VERSION ""

NS_ :

BS_:

BU_: VCU INVOBC
VAL_TABLE_ Vt_INVCH_SignalDSP_state 43 "CTRL_STATE_EXPORT_SHUTDOWN_4" 42 "CTRL_STATE_EXPORT_SHUTDOWN_3" 41 "CTRL_STATE_EXPORT_SHUTDOWN_2" 40 "CTRL_STATE_EXPORT_SHUTDOWN_1" 39 "CTRL_STATE_NA" 38 "CTRL_STATE_NA" 37 "CTRL_STATE_NA" 36 "CTRL_STATE_NA" 35 "CTRL_STATE_NA" 34 "CTRL_STATE_EXPORT_ALCI" 33 "CTRL_STATE_EXPORT_SHUTDOWN" 32 "CTRL_STATE_EXPORT_ENERGY" 31 "CTRL_STATE_EXPORT_DISABLED" 30 "CTRL_STATE_EXPORT_INIT" 29 "CTRL_STATE_NA" 28 "CTRL_STATE_NA" 27 "CTRL_STATE_NA" 26 "CTRL_STATE_NA" 25 "CTRL_STATE_NA" 24 "CTRL_STATE_NA" 23 "CTRL_STATE_CHARGER_SHUTDOWN_4" 22 "CTRL_STATE_CHARGER_SHUTDOWN_3" 21 "CTRL_STATE_CHARGER_SHUTDOWN_2" 20 "CTRL_STATE_CHARGER_SHUTDOWN_1" 19 "CTRL_STATE_NA" 18 "CTRL_STATE_NA" 17 "CTRL_STATE_NA" 16 "CTRL_STATE_NA" 15 "CTRL_STATE_VEHICLE_DOWN_CHARGER" 14 "CTRL_STATE_VEHICLE_ERROR" 13 "CTRL_STATE_VEHICLE_ENERGY_DISC_E" 12 "CTRL_STATE_VEHICLE_ACCEPT_CD" 11 "CTRL_STATE_VEHICLE_CONNECTED_B" 10 "CTRL_STATE_VEHICLE_NOT_CON_A" 9 "CTRL_STATE_MODULE_DEBUG" 8 "CTRL_STATE_MODULE_STAND_BY" 7 "CTRL_STATE_MODULE_EXPORT" 6 "CTRL_STATE_MODULE_TEST" 5 "CTRL_STATE_MODULE_DELAYED_SLEEP" 4 "CTRL_STATE_MODULE_SLEEP" 3 "CTRL_STATE_MODULE_OTP" 2 "CTRL_STATE_MODULE_VEHICLE_CHARGE" 1 "CTRL_STATE_MODULE_WAKE_UP" 0 "CTRL_STATE_MODULE_INIT" ;
VAL_TABLE_ Vt_Unit_ready 1 "Unit is ready" 0 "Unit is NOT ready" ;
VAL_TABLE_ Vt_Chg_Vehicle_States 6 "State F" 5 "State E" 4 "State D" 3 "State C" 2 "State B" 1 "State A" ;
VAL_TABLE_ Vt_Signal_State 43 "CTRL_STATE_EXPORT_SHUTDOWN_4" 42 "CTRL_STATE_EXPORT_SHUTDOWN_3" 41 "CTRL_STATE_EXPORT_SHUTDOWN_2" 40 "CTRL_STATE_EXPORT_SHUTDOWN_1" 39 "CTRL_STATE_NA" 38 "CTRL_STATE_NA" 37 "CTRL_STATE_NA" 36 "CTRL_STATE_NA" 35 "CTRL_STATE_NA" 34 "CTRL_STATE_EXPORT_ALCI" 33 "CTRL_STATE_EXPORT_SHUTDOWN" 32 "CTRL_STATE_EXPORT_ENERGY" 31 "CTRL_STATE_EXPORT_DISABLED" 30 "CTRL_STATE_EXPORT_INIT" 29 "CTRL_STATE_NA" 28 "CTRL_STATE_NA" 27 "CTRL_STATE_NA" 26 "CTRL_STATE_NA" 25 "CTRL_STATE_NA" 24 "CTRL_STATE_NA" 23 "CTRL_STATE_CHARGER_SHUTDOWN_4" 22 "CTRL_STATE_CHARGER_SHUTDOWN_3" 21 "CTRL_STATE_CHARGER_SHUTDOWN_2" 20 "CTRL_STATE_CHARGER_SHUTDOWN_1" 19 "CTRL_STATE_NA" 18 "CTRL_STATE_NA" 17 "CTRL_STATE_NA" 16 "CTRL_STATE_NA" 15 "CTRL_STATE_VEHICLE_SHDN_CHARGER" 14 "CTRL_STATE_VEHICLE_ERROR" 13 "CTRL_STATE_VEHICLE_ENERGY_DISC_E" 12 "CTRL_STATE_VEHICLE_ACCEPT_ENG_CD" 11 "CTRL_STATE_VEHICLE_CONNECTED_B" 10 "CTRL_STATE_VEHICLE_NOT_CON_A" 9 "CTRL_STATE_NA" 8 "CTRL_STATE_MODULE_DEBUG" 7 "CTRL_STATE_MODULE_EXPORT" 6 "CTRL_STATE_MODULE_TEST" 5 "CTRL_STATE_MODULE_DELAYED_SLEEP" 4 "CTRL_STATE_MODULE_SLEEP" 3 "CTRL_STATE_MODULE_PREPARE_SLEEP" 2 "CTRL_STATE_MODULE_VEHICLE_CHARGE" 1 "CTRL_STATE_MODULE_WAKE_UP" 0 "CTRL_STATE_MODULE_INIT" ;
VAL_TABLE_ Vt_ALCI_test 1 "Perform ALCI test" ;
VAL_TABLE_ Vt_LED_Mode 2 "FLASH" 1 "SOLID" 0 "OFF" ;
VAL_TABLE_ Vt_Pilot_Impedance 1 "State C" 0 "State B" ;
VAL_TABLE_ Vt_WOC_Mode 2 "WOC_mode_VcuReWake" 1 "WOC_mode_delayed_module_sleep" 0 "WOC_mode_Sleep" ;
VAL_TABLE_ Vt_Wake_Signal 1 "Turn ON WAKE output" 0 "Turn OFF WAKE output" ;
VAL_TABLE_ Vt_Mode 1 "Charger Mode" 0 "Export Power Mode" ;
VAL_TABLE_ Vt_Enable 1 "Turn ON oputput" 0 "Turn OFF output" ;

BO_ 3221225472 VECTOR__INDEPENDENT_SIG_MSG: 0 Vector__XXX
 SG_ INVCH_Bdc_SignalDSP_State : 0|8@1+ (1,0) [0|255] "" Vector__XXX
 SG_ INVCH_Bdc_TempPercent : 0|8@1+ (1,0) [0|100] "%" Vector__XXX
 SG_ INVCH_Bdc_Temperature_Int : 0|16@1- (0.1,0) [-100|200] "degC" Vector__XXX
 SG_ INVCH_Bdc_Temperature_Bb : 0|16@1- (0.1,0) [-100|200] "degC" Vector__XXX
 SG_ INVCH_Bdc_Temperature_Inv : 0|16@1- (0.1,0) [-100|200] "degC" Vector__XXX
 SG_ INVCH_Bdc_TempPercent : 0|8@1+ (1,0) [0|100] "%" Vector__XXX
 SG_ INVCH_Bdc_Temperature_Int : 0|16@1- (0.1,0) [-100|200] "degC" Vector__XXX
 SG_ INVCH_Bdc_Temperature_Bb : 0|16@1- (0.1,0) [-100|200] "degC" Vector__XXX
 SG_ INVCH_Bdc_Bb_BBTemp : 0|16@1- (0.1,0) [-100|200] "degC" Vector__XXX
 SG_ INVCH_Bdc_Bb_BBIntTemp : 0|16@1- (0.1,0) [-100|200] "degC" Vector__XXX
 SG_ INVCH_Bdc_Bb_BBDC2Temp : 0|16@1- (0.1,0) [-100|200] "degC" Vector__XXX
 SG_ INVCH_Bdc_Bb_BBDC1Temp : 0|16@1- (0.1,0) [-100|200] "degC" Vector__XXX
 SG_ INVCH_Bdc_Inv_TempInv2Deg : 0|16@1- (0.1,0) [-100|200] "degC" Vector__XXX
 SG_ INVCH_Bdc_Inv_TempInv1Deg : 0|16@1- (0.1,0) [-100|200] "degC" Vector__XXX
 SG_ INVCH_Bdc_Inv_TempDcDc2Deg : 0|16@1- (0.1,0) [-100|200] "degC" Vector__XXX
 SG_ INVCH_Bdc_Inv_TempDcDc1Deg : 0|16@1- (0.1,0) [-100|200] "degC" Vector__XXX
 SG_ INVCH_Bdc_Chg_Vehicle_State : 0|8@1+ (1,0) [0|10] "" Vector__XXX
 SG_ INVCH_Chg_Ibat_max_available : 0|16@1+ (0.05,0) [0|80] "A" Vector__XXX
 SG_ INVCH_Bdc_bEVSEMode : 0|1@1+ (1,0) [0|1] "" Vector__XXX
 SG_ INVCH_Bdc_bExport50Hz : 0|1@1+ (1,0) [0|1] "" Vector__XXX
 SG_ INVCH_Bdc_bAutoLowPower : 0|1@1+ (1,0) [0|1] "" Vector__XXX
 SG_ INVCH_Bdc_bEVSEDisConnected : 0|1@1+ (1,0) [0|1] "" Vector__XXX
 SG_ INVCH_Bdc_Error_bFreqOver : 0|1@1+ (1,0) [0|1] "" Vector__XXX
 SG_ INVCH_Bdc_Error_bFreqUnder : 0|1@1+ (1,0) [0|1] "" Vector__XXX
 SG_ INVCH_Bdc_Error_bExtCanFail : 0|1@1+ (1,0) [0|1] "" Vector__XXX
 SG_ INVCH_Bdc_Signal_ShutDown_State : 0|8@1- (1,0) [0|0] "" Vector__XXX
 SG_ INVCH_Bdc_ShutDown_Source : 0|8@1+ (1,0) [0|0] "" Vector__XXX
 SG_ INVCH_Bdc_Error_bWakeOutputError : 0|1@1+ (1,0) [0|1] "" Vector__XXX
 SG_ INVCH_Bdc_Error_bOTP : 0|1@1+ (1,0) [0|1] "" Vector__XXX
 SG_ INVCH_Bdc_Error_bInverterFault : 0|1@1+ (1,0) [0|1] "" Vector__XXX
 SG_ INVCH_Bdc_Error_bHVBatteryUV : 0|1@1+ (1,0) [0|1] "" Vector__XXX
 SG_ INVCH_Bdc_Error_bHVBatteryOV : 0|1@1+ (1,0) [0|1] "" Vector__XXX
 SG_ INVCH_Bdc_Error_bExportOverload : 0|1@1+ (1,0) [0|1] "" Vector__XXX
 SG_ INVCH_Bdc_Error_bBBFault : 0|1@1+ (1,0) [0|1] "" Vector__XXX
 SG_ INVCH_Bdc_Error_bBatteryUV : 0|1@1+ (1,0) [0|1] "" Vector__XXX
 SG_ INVCH_Bdc_Error_bACUV : 0|1@1+ (1,0) [0|1] "" Vector__XXX
 SG_ INVCH_Bdc_Error_bACOV : 0|1@1+ (1,0) [0|1] "" Vector__XXX
 SG_ INVCH_Bdc_Error_bACOk : 0|1@1+ (1,0) [0|1] "" Vector__XXX
 SG_ INVCH_Bdc_Inverter_Status : 0|8@1+ (1,0) [0|10] "" Vector__XXX
 SG_ INVCH_Bdc_BuckBoost_Status : 0|8@1+ (1,0) [0|10] "" Vector__XXX
 SG_ INVCH_Bdc_bStandBy : 0|1@1+ (1,0) [0|1] "" Vector__XXX
 SG_ INVCH_Bdc_bLowPowerMode : 0|1@1+ (1,0) [0|1] "" Vector__XXX
 SG_ INVCH_Bdc_bGridTied : 0|1@1+ (1,0) [0|1] "" Vector__XXX
 SG_ INVCH_Bdc_bUnitReady : 0|1@1+ (1,0) [0|1] "" Vector__XXX
 SG_ INVCH_Bdc_Signal_State : 0|8@1+ (1,0) [0|0] "" Vector__XXX
 SG_ INVCH_Bdc_bWakeOutputOn : 0|1@1+ (1,0) [0|1] "" Vector__XXX
 SG_ INVCH_Bdc_bVehicleConnected : 0|1@1+ (1,0) [0|1] "" Vector__XXX
 SG_ INVCH_Bdc_bReWaked : 0|1@1+ (1,0) [0|1] "" Vector__XXX
 SG_ INVCH_Bdc_bProximityEn : 0|1@1+ (1,0) [0|1] "" Vector__XXX
 SG_ INVCH_Bdc_bPilotInPwm : 0|1@1+ (1,0) [0|1] "" Vector__XXX
 SG_ INVCH_Bdc_bSwitchS2En : 0|1@1+ (1,0) [0|1] "" Vector__XXX
 SG_ INVCH_Bdc_bModuleDelayledSleepM : 0|1@1+ (1,0) [0|1] "" Vector__XXX
 SG_ INVCH_Bdc_bKeySwitch : 0|1@1+ (1,0) [0|1] "" Vector__XXX
 SG_ INVCH_Bdc_bInvReady : 0|1@1+ (1,0) [0|1] "" Vector__XXX
 SG_ INVCH_Bdc_bInvAlive : 0|1@1+ (1,0) [0|1] "" Vector__XXX
 SG_ INVCH_Bdc_bExporting : 0|1@1+ (1,0) [0|1] "" Vector__XXX
 SG_ INVCH_Bdc_bExportEnergyEn : 0|1@1+ (1,0) [0|1] "" Vector__XXX
 SG_ INVCH_Bdc_bEVSEConnected : 0|1@1+ (1,0) [0|1] "" Vector__XXX
 SG_ INVCH_Bdc_bCharging : 0|1@1+ (1,0) [0|1] "" Vector__XXX
 SG_ INVCH_Bdc_bBBReady : 0|1@1+ (1,0) [0|1] "" Vector__XXX
 SG_ INVCH_Bdc_bBBAlive : 0|1@1+ (1,0) [0|1] "" Vector__XXX
 SG_ INVCH_Bdc_bAuxEn : 0|1@1+ (1,0) [0|1] "" Vector__XXX
 SG_ INVCH_Bdc_bAlciReset : 0|1@1+ (1,0) [0|1] "" Vector__XXX
 SG_ INVCH_Bdc_bAlciActive : 0|1@1+ (1,0) [0|1] "" Vector__XXX
 SG_ INVCH_Bdc_bChrgEnergyFlowEn : 0|1@1+ (1,0) [0|1] "" Vector__XXX
 SG_ INVCH_Index : 0|8@1+ (1,0) [0|255] "" Vector__XXX
 SG_ INVCH_Inv_Freq : 0|8@1+ (1,0) [0|255] "Hz" Vector__XXX
 SG_ INVCH_Inv_Volt : 0|8@1+ (1,0) [0|255] "Vac" Vector__XXX
 SG_ INVCH_Bdc_inv_alci_disable : 0|8@1+ (1,0) [1|255] "" Vector__XXX
 SG_ INVCH_Bdc_12V_Battery_UV_Limit : 0|16@1+ (0.001,0) [0|65.535] "V" Vector__XXX
 SG_ INVCH_Chg_Iac_Lim : 0|16@1+ (0.05,0) [0|80] "A" Vector__XXX
 SG_ INVCH_Chg_EVSE_Mode : 0|8@1+ (1,0) [0|255] "" Vector__XXX
 SG_ INVCH_Bdc_Battery_StateOfCharge : 0|8@1+ (1,0) [0|100] "" Vector__XXX
 SG_ INVCH_Index3 : 0|8@1+ (1,0) [0|255] "" Vector__XXX
 SG_ INVCH_Bdc_lcd_ch9 : 0|8@1+ (1,0) [0|255] "" Vector__XXX
 SG_ INVCH_Bdc_lcd_ch8 : 0|8@1+ (1,0) [0|255] "" Vector__XXX
 SG_ INVCH_Bdc_lcd_ch7 : 0|8@1+ (1,0) [0|255] "" Vector__XXX
 SG_ INVCH_Bdc_lcd_ch6 : 0|8@1+ (1,0) [0|255] "" Vector__XXX
 SG_ INVCH_Bdc_lcd_ch5 : 0|8@1+ (1,0) [0|255] "" Vector__XXX
 SG_ INVCH_Bdc_lcd_ch4 : 0|8@1+ (1,0) [0|255] "" Vector__XXX
 SG_ INVCH_Bdc_lcd_ch32 : 0|8@1+ (1,0) [0|255] "" Vector__XXX
 SG_ INVCH_Bdc_lcd_ch31 : 0|8@1+ (1,0) [0|255] "" Vector__XXX
 SG_ INVCH_Bdc_lcd_ch30 : 0|8@1+ (1,0) [0|255] "" Vector__XXX
 SG_ INVCH_Bdc_lcd_ch3 : 0|8@1+ (1,0) [0|255] "" Vector__XXX
 SG_ INVCH_Bdc_lcd_ch29 : 0|8@1+ (1,0) [0|255] "" Vector__XXX
 SG_ INVCH_Bdc_lcd_ch28 : 0|8@1+ (1,0) [0|255] "" Vector__XXX
 SG_ INVCH_Bdc_lcd_ch27 : 0|8@1+ (1,0) [0|255] "" Vector__XXX
 SG_ INVCH_Bdc_lcd_ch26 : 0|8@1+ (1,0) [0|255] "" Vector__XXX
 SG_ INVCH_Bdc_lcd_ch25 : 0|8@1+ (1,0) [0|255] "" Vector__XXX
 SG_ INVCH_Bdc_lcd_ch24 : 0|8@1+ (1,0) [0|255] "" Vector__XXX
 SG_ INVCH_Bdc_lcd_ch23 : 0|8@1+ (1,0) [0|255] "" Vector__XXX
 SG_ INVCH_Bdc_lcd_ch22 : 0|8@1+ (1,0) [0|255] "" Vector__XXX
 SG_ INVCH_Bdc_lcd_ch21 : 0|8@1+ (1,0) [0|255] "" Vector__XXX
 SG_ INVCH_Bdc_lcd_ch20 : 0|8@1+ (1,0) [0|255] "" Vector__XXX
 SG_ INVCH_Bdc_lcd_ch2 : 0|8@1+ (1,0) [0|255] "" Vector__XXX
 SG_ INVCH_Bdc_lcd_ch19 : 0|8@1+ (1,0) [0|255] "" Vector__XXX
 SG_ INVCH_Bdc_lcd_ch18 : 0|8@1+ (1,0) [0|255] "" Vector__XXX
 SG_ INVCH_Bdc_lcd_ch17 : 0|8@1+ (1,0) [0|255] "" Vector__XXX
 SG_ INVCH_Bdc_lcd_ch16 : 0|8@1+ (1,0) [0|255] "" Vector__XXX
 SG_ INVCH_Bdc_lcd_ch15 : 0|8@1+ (1,0) [0|255] "" Vector__XXX
 SG_ INVCH_Bdc_lcd_ch14 : 0|8@1+ (1,0) [0|255] "" Vector__XXX
 SG_ INVCH_Bdc_lcd_ch13 : 0|8@1+ (1,0) [0|255] "" Vector__XXX
 SG_ INVCH_Bdc_lcd_ch12 : 0|8@1+ (1,0) [0|255] "" Vector__XXX
 SG_ INVCH_Bdc_lcd_ch11 : 0|8@1+ (1,0) [0|255] "" Vector__XXX
 SG_ INVCH_Bdc_lcd_ch10 : 0|8@1+ (1,0) [0|255] "" Vector__XXX
 SG_ INVCH_Bdc_lcd_ch1 : 0|8@1+ (1,0) [0|255] "" Vector__XXX
 SG_ INVCH_Bdc_inv_alci_test : 0|8@1+ (1,0) [1|1] "" Vector__XXX
 SG_ INVCH_Bdc_inv_alci_LED_bright : 0|8@1+ (0.5,0) [0|100] "%" Vector__XXX
 SG_ INVCH_Bdc_LED_On_timer : 0|16@1+ (1,0) [0|65535] "min" Vector__XXX
 SG_ INVCH_Bdc_LED2_phase : 0|16@1- (1,0) [0|65535] "ms" Vector__XXX
 SG_ INVCH_Bdc_LED2_on_time : 0|8@1+ (50,0) [0|12750] "ms" Vector__XXX
 SG_ INVCH_Bdc_LED2_mode : 0|8@1+ (1,0) [0|2] "" Vector__XXX
 SG_ INVCH_Bdc_LED2_duty : 0|8@1+ (1,0) [0|100] "%" Vector__XXX
 SG_ INVCH_Bdc_LED2_bright : 0|8@1+ (0.5,0) [0|100] "%" Vector__XXX
 SG_ INVCH_Bdc_LED1_on_time : 0|8@1+ (50,0) [0|12750] "ms" Vector__XXX
 SG_ INVCH_Bdc_LED1_mode : 0|8@1+ (1,0) [0|2] "" Vector__XXX
 SG_ INVCH_Bdc_LED1_duty : 0|8@1+ (1,0) [0|100] "%" Vector__XXX
 SG_ INVCH_Bdc_LED1_bright : 0|8@1+ (0.5,0) [0|100] "%" Vector__XXX
 SG_ INVCH_Bdc_woc_undervoltage_set : 0|16@1+ (0.001,0) [0|0] "V" Vector__XXX
 SG_ INVCH_Bdc_woc_undervoltage_act : 0|8@1+ (1,0) [0|2] "" Vector__XXX
 SG_ INVCH_Bdc_woc_timer_delay_action : 0|8@1+ (1,0) [0|2] "" Vector__XXX
 SG_ INVCH_Bdc_woc_timer_delay : 0|16@1+ (1,0) [0|65535] "min" Vector__XXX
 SG_ INVCH_Bdc_woc_mode : 0|8@1+ (1,0) [0|2] "" Vector__XXX
 SG_ INVCH_Bdc_woc_control_pilot_imp : 0|8@1+ (1,0) [0|1] "" Vector__XXX
 SG_ INVCH_Bdc_woc_wake : 0|8@1+ (1,0) [0|1] "" Vector__XXX
 SG_ INVCH_Inv_Vbat_UV_lim : 0|16@1+ (0.05,0) [0|3276.75] "Vdc" Vector__XXX
 SG_ INVCH_Chg_Ibat_lim : 0|16@1+ (0.05,0) [0|80] "A" Vector__XXX
 SG_ INVCH_Chg_Vbat_lim : 0|16@1+ (0.05,0) [0|500] "Vdc" Vector__XXX
 SG_ INVCH_Bdc_cmd_Mode : 0|8@1+ (1,0) [0|1] "" Vector__XXX
 SG_ INVCH_Bdc_cmd_Enable : 0|8@1+ (1,0) [0|1] "" Vector__XXX
 SG_ INVCH_Bdc_On_Time : 0|24@1+ (1,0) [0|16777215] "min" Vector__XXX
 SG_ INVCH_Chg_Pilot_Freq : 0|16@1+ (1,0) [0|1500] "Hz" Vector__XXX
 SG_ INVCH_Chg_Pilot_Duty : 0|8@1+ (1,0) [0|100] "%" Vector__XXX
 SG_ INVCH_Bdc_12Vbat : 0|16@1+ (0.02,0) [0|1310.7] "V" Vector__XXX
 SG_ INVCH_Bdc_TempPercent : 0|8@1+ (1,0) [0|100] "%" Vector__XXX
 SG_ INVCH_Bdc_Temperature_Int : 0|16@1- (0.1,0) [-100|200] "degC" Vector__XXX
 SG_ INVCH_Bdc_Temperature_Bb : 0|16@1- (0.1,0) [-100|200] "degC" Vector__XXX
 SG_ INVCH_Bdc_Temperature_Inv : 0|16@1- (0.1,0) [-100|200] "degC" Vector__XXX
 SG_ INVCH_Chg_Iin_RMS : 0|16@1+ (0.05,0) [0|200] "A" Vector__XXX
 SG_ INVCH_Chg_Vin_RMS : 0|16@1+ (0.05,0) [0|300] "V" Vector__XXX
 SG_ INVCH_Bdc_Ibat : 0|16@1- (0.05,0) [-50|50] "A" Vector__XXX
 SG_ INVCH_Bdc_Vbat : 0|16@1+ (0.05,0) [0|500] "V" Vector__XXX
 SG_ INVCH_Inv_Iout2_RMS : 0|16@1+ (0.05,0) [0|100] "A" Vector__XXX
 SG_ INVCH_Inv_Iout1_RMS : 0|16@1+ (0.05,0) [0|100] "A" Vector__XXX
 SG_ INVCH_Inv_Vout2_RMS : 0|16@1+ (0.05,0) [0|200] "V" Vector__XXX
 SG_ INVCH_Inv_Vout1_RMS : 0|16@1+ (0.05,0) [0|200] "V" Vector__XXX
 SG_ ParameterGroupNumber : 0|24@1+ (1,0) [0|0] "" Vector__XXX

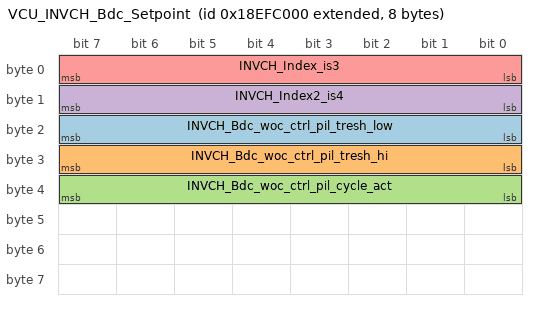
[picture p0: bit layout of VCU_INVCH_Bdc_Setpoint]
BO_ 2565849088 VCU_INVCH_Bdc_Setpoint: 8 VCU
 SG_ INVCH_Bdc_woc_ctrl_pil_tresh_low : 16|8@1+ (1,0) [3|97] "%" Vector__XXX
 SG_ INVCH_Bdc_woc_ctrl_pil_tresh_hi : 24|8@1+ (1,0) [3|97] "%" Vector__XXX
 SG_ INVCH_Bdc_woc_ctrl_pil_cycle_act : 32|8@1+ (1,0) [0|2] "" Vector__XXX
 SG_ INVCH_Index2_is4 : 8|8@1+ (1,0) [0|255] "" Vector__XXX
 SG_ INVCH_Index_is3 : 0|8@1+ (1,0) [0|255] "" Vector__XXX

CM_ BO_ 3221225472 "This is a message for not used signals, created by Vector CANdb++ DBC OLE DB Provider.";
BA_DEF_ SG_  "SigType" ENUM  "Default","Range","RangeSigned","ASCII","Discrete","Control","ReferencePGN","DTC","StringDelimiter","StringLength","StringLengthControl";
BA_DEF_ SG_  "GenSigEVName" STRING ;
BA_DEF_ SG_  "GenSigILSupport" ENUM  "No","Yes";
BA_DEF_ SG_  "GenSigSendType" ENUM  "Cyclic","OnWrite","OnWriteWithRepetition","OnChange","OnChangeWithRepetition","IfActive","IfActiveWithRepetition","NoSigSendType";
BA_DEF_ SG_  "GenSigStartValue" INT 0 10000;
BA_DEF_ BO_  "GenMsgILSupport" ENUM  "No","Yes";
BA_DEF_ BU_  "NmStationAddress" INT 0 255;
BA_DEF_ BO_  "GenMsgSendType" ENUM  "cyclic","NotUsed","IfActive","NotUsed","NotUsed","NotUsed","NotUsed","NotUsed","noMsgSendType";
BA_DEF_ BO_  "GenMsgRequestable" INT 0 1;
BA_DEF_ BO_  "GenMsgCycleTime" INT 0 3600000;
BA_DEF_  "DBName" STRING ;
BA_DEF_  "BusType" STRING ;
BA_DEF_  "ProtocolType" STRING ;
BA_DEF_ BO_  "VFrameFormat" ENUM  "StandardCAN","ExtendedCAN","reserved","J1939PG";
BA_DEF_DEF_  "SigType" "Default";
BA_DEF_DEF_  "GenSigEVName" "Env@Nodename_@Signame";
BA_DEF_DEF_  "GenSigILSupport" "Yes";
BA_DEF_DEF_  "GenSigSendType" "NoSigSendType";
BA_DEF_DEF_  "GenSigStartValue" 0;
BA_DEF_DEF_  "GenMsgILSupport" "Yes";
BA_DEF_DEF_  "NmStationAddress" 254;
BA_DEF_DEF_  "GenMsgSendType" "noMsgSendType";
BA_DEF_DEF_  "GenMsgRequestable" 1;
BA_DEF_DEF_  "GenMsgCycleTime" 0;
BA_DEF_DEF_  "DBName" "";
BA_DEF_DEF_  "BusType" "CAN";
BA_DEF_DEF_  "ProtocolType" "J1939";
BA_DEF_DEF_  "VFrameFormat" "J1939PG";
BA_ "ProtocolType" "";
BA_ "DBName" "Node_INVOBC";
BA_ "NmStationAddress" BU_ VCU 97;
BA_ "NmStationAddress" BU_ INVOBC 192;
BA_ "VFrameFormat" BO_ 2565849088 1;
BA_ "GenMsgCycleTime" BO_ 2565849088 100;
BA_ "GenSigStartValue" SG_ 3221225472 INVCH_Bdc_inv_alci_disable 1;
BA_ "GenSigStartValue" SG_ 3221225472 INVCH_Bdc_inv_alci_test 1;
BA_ "GenSigStartValue" SG_ 2565849088 INVCH_Bdc_woc_ctrl_pil_tresh_low 3;
BA_ "GenSigStartValue" SG_ 2565849088 INVCH_Bdc_woc_ctrl_pil_tresh_hi 3;
VAL_ 3221225472 INVCH_Bdc_Chg_Vehicle_State 6 "State F" 5 "State E" 4 "State D" 3 "State C" 2 "State B" 1 "State A" ;
VAL_ 3221225472 INVCH_Bdc_Signal_ShutDown_State 0 "INIT" 1 "WAKE_UP" 2 "VEH_CHARGE" 3 "OTP" 4 "SLEEP" 5 "DELAYED_SLEEP" 6 "TEST" 7 "EXPORT" 8 "STANDBY" 9 "DEBUG" 10 "NOT_CONN_A" 11 "CONN_B" 12 "ACCEPT_ENERGY_CD" 13 "ENERGY_DISC_E" 14 "ERR" 15 "SHUTDOWN_CHARGER" 20 "CHRGR_SHTDOWN_1" 21 "CHRGR_SHTDOWN_2" 22 "CHRGR_SHTDOWN_3" 23 "CHRGR_SHTDOWN_4" 30 "EXP_INIT" 31 "EXP_DISABLED" 32 "EXP_ENERGY" 33 "EXP_SHTDOWN" 34 "EXP_ALCI" 40 "EXP_SHTDWN_1" 41 "EXP_SHTDWN_2" 42 "EXP_SHTDWN_3" 43 "EXP_SHTDWN_4" ;
VAL_ 3221225472 INVCH_Bdc_ShutDown_Source 19 "AC_OV_FAIL" 18 "AC_UV_FAIL" 17 "FREQ_OVER_FAIL" 16 "FREQ_UNDER_FAIL" 15 "EXT_CAN_TIMEOUT" 14 "DELAYED_SLEEP" 13 "BUCKBOOST_CAN_FAIL" 12 "INVERTER_CAN_FAIL" 11 "PROXIMITY" 10 "PILOT" 9 "S2_SWITCH" 8 "HV_BATTERY_UV" 7 "HV_BATTERY_OV" 6 "OTP" 5 "AC_FAIL" 4 "BUCKBOOST_ERROR" 3 "INVERTER_ERROR" 2 "KEY_SWITCH" 1 "COMMAND" 0 "NONE" ;
VAL_ 3221225472 INVCH_Bdc_Inverter_Status 34 "INV_HICCUP" 33 "PFC_ENABLE_N" 32 "INV_ENABLE_N" 31 "INV_DC_DEBUG_NO_PROT" 30 "WATCHDOG" 29 "PFC_AC_UV_OV" 28 "INV_DC_DEBUG" 27 "DC_DEBUG" 26 "PFC_RUNNING" 25 "PFC_RELAY_START" 24 "PFC_SOFTSTART" 23 "PFC_DRIVER_SOFTSTART" 22 "PFC_DEBUG" 21 "INV_RELAY_START" 20 "ALCI_ACTIVE" 19 "INV_DRIVER_SOFTSTART" 18 "PFC_DC_UV_OV" 17 "GOTO_SLEEP" 16 "JUMP_BOOTLOADER" 15 "SOFTSTART" 14 "BB_SOFTSTART" 13 "INV_SOFTSTART" 12 "SHORTCIRCUIT" 11 "OVERLOAD" 10 "DRIVER_FAULT" 9 "INIT" 8 "INV_DEBUG" 7 "OTP" 6 "BUS_ERROR" 5 "LATCHED_FAULT" 4 "INV_RUNNING" 3 "INV_STARTUP" 2 "INV_UV_OV" 1 "IDDLE" 0 "FIRST_START" ;
VAL_ 3221225472 INVCH_Bdc_BuckBoost_Status 20 "WATCHDOG" 19 "DC_DEBUG" 18 "BB_DEBUG" 17 "GOTO_SLEEP" 16 "JUMP_BOOTLOADER" 15 "SOFTSTART" 14 "BB_SOFTSTART" 13 "DCDC_SOFTSTART" 12 "SHORTCIRCUIT" 11 "OVERLOAD" 10 "DRIVER_FAULT" 9 "INIT" 8 "DEBUG" 7 "OTP" 6 "BUS_ERROR" 5 "LATCHED_FAULT" 4 "RUNNING" 3 "STARTUP" 2 "UV_OV" 1 "IDDLE" 0 "FIRST_START" ;
VAL_ 3221225472 INVCH_Bdc_bUnitReady 1 "Unit is ready" 0 "Unit is NOT ready" ;
VAL_ 3221225472 INVCH_Bdc_Signal_State 0 "INIT" 1 "WAKE_UP" 2 "VEH_CHARGE" 3 "OTP" 4 "SLEEP" 5 "DELAYED_SLEEP" 6 "TEST" 7 "EXPORT" 8 "STANDBY" 9 "DEBUG" 10 "NOT_CONN_A" 11 "CONN_B" 12 "ACCEPT_ENERGY_CD" 13 "ENERGY_DISC_E" 14 "ERR" 15 "SHUTDOWN_CHARGER" 20 "CHRGR_SHTDOWN_1" 21 "CHRGR_SHTDOWN_2" 22 "CHRGR_SHTDOWN_3" 23 "CHRGR_SHTDOWN_4" 30 "EXP_INIT" 31 "EXP_DISABLED" 32 "EXP_ENERGY" 33 "EXP_SHTDOWN" 34 "EXP_ALCI" 40 "EXP_SHTDWN_1" 41 "EXP_SHTDWN_2" 42 "EXP_SHTDWN_3" 43 "EXP_SHTDWN_4" ;
VAL_ 3221225472 INVCH_Bdc_inv_alci_disable 1 "Disable ALCI" ;
VAL_ 3221225472 INVCH_Bdc_inv_alci_test 1 "Perform ALCI test" ;
VAL_ 3221225472 INVCH_Bdc_LED2_mode 2 "FLASH" 1 "SOLID" 0 "OFF" ;
VAL_ 3221225472 INVCH_Bdc_LED1_mode 2 "FLASH" 1 "SOLID" 0 "OFF" ;
VAL_ 3221225472 INVCH_Bdc_woc_undervoltage_act 2 "WOC_VcuReWake" 1 "WOC_sleep" 0 "WOC_no_action" ;
VAL_ 3221225472 INVCH_Bdc_woc_timer_delay_action 2 "WOC_VcuReWake" 1 "WOC_sleep" 0 "WOC_no_action" ;
VAL_ 3221225472 INVCH_Bdc_woc_mode 2 "WOC_mode_VcuReWake" 1 "WOC_mode_delayed_module_sleep" 0 "WOC_mode_Sleep" ;
VAL_ 3221225472 INVCH_Bdc_woc_control_pilot_imp 1 "State C" 0 "State B" ;
VAL_ 3221225472 INVCH_Bdc_woc_wake 1 "Turn ON WAKE output" 0 "Turn OFF WAKE output" ;
VAL_ 3221225472 INVCH_Bdc_cmd_Mode 3 "Charger Low Power Mode" 2 "Stand-By" 1 "Charger Mode" 0 "Export Power Mode" ;
VAL_ 3221225472 INVCH_Bdc_cmd_Enable 1 "Turn ON oputput" 0 "Turn OFF output" ;
VAL_ 3221225472 ParameterGroupNumber 65259 "Component ID" 65242 "Software version" ;
VAL_ 2565849088 INVCH_Bdc_woc_ctrl_pil_cycle_act 2 "WOC_VcuReWake" 1 "WOC_sleep" 0 "WOC_no_action" ;
